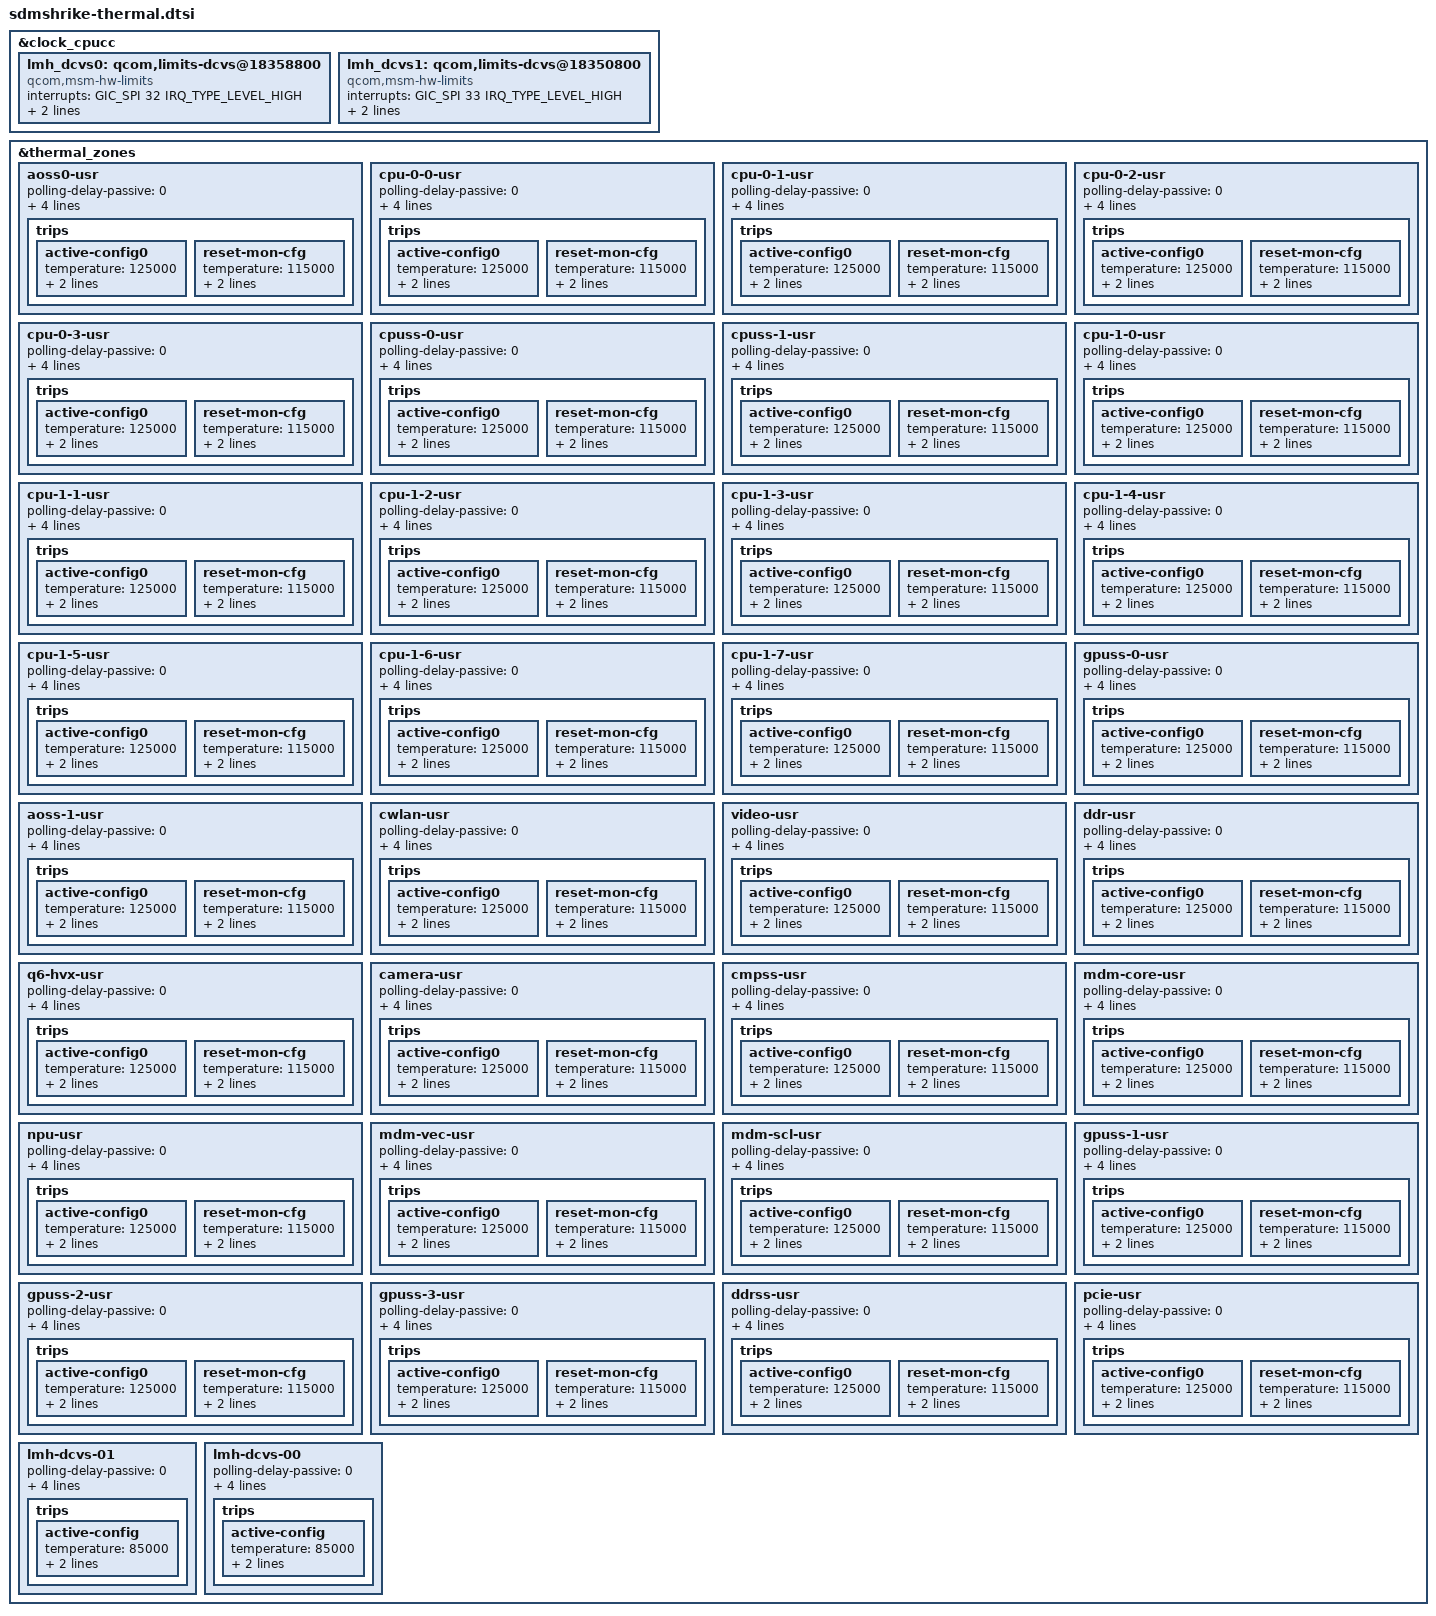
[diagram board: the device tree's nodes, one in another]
/* Copyright (c) 2019, The Linux Foundation. All rights reserved.
 *
 * This program is free software; you can redistribute it and/or modify
 * it under the terms of the GNU General Public License version 2 and
 * only version 2 as published by the Free Software Foundation.
 *
 * This program is distributed in the hope that it will be useful,
 * but WITHOUT ANY WARRANTY; without even the implied warranty of
 * MERCHANTABILITY or FITNESS FOR A PARTICULAR PURPOSE.  See the
 * GNU General Public License for more details.
 */

#include <dt-bindings/thermal/thermal.h>

&clock_cpucc {
	#address-cells = <1>;
	#size-cells = <1>;
	lmh_dcvs0: qcom,limits-dcvs@18358800 {
		compatible = "qcom,msm-hw-limits";
		interrupts = <GIC_SPI 32 IRQ_TYPE_LEVEL_HIGH>;
		qcom,affinity = <0>;
		reg = <0x18358800 0x1000>,
			<0x18323000 0x1000>;
		#thermal-sensor-cells = <0>;
	};

	lmh_dcvs1: qcom,limits-dcvs@18350800 {
		compatible = "qcom,msm-hw-limits";
		interrupts = <GIC_SPI 33 IRQ_TYPE_LEVEL_HIGH>;
		qcom,affinity = <1>;
		reg = <0x18350800 0x1000>,
			<0x18325800 0x1000>;
		#thermal-sensor-cells = <0>;
	};
};

&thermal_zones {
	aoss0-usr {
		polling-delay-passive = <0>;
		polling-delay = <0>;
		thermal-governor = "user_space";
		thermal-sensors = <&tsens0 0>;
		wake-capable-sensor;
		trips {
			active-config0 {
				temperature = <125000>;
				hysteresis = <1000>;
				type = "passive";
			};
			reset-mon-cfg {
				temperature = <115000>;
				hysteresis = <5000>;
				type = "passive";
			};
		};
	};

	cpu-0-0-usr {
		polling-delay-passive = <0>;
		polling-delay = <0>;
		thermal-governor = "user_space";
		thermal-sensors = <&tsens0 1>;
		wake-capable-sensor;
		trips {
			active-config0 {
				temperature = <125000>;
				hysteresis = <1000>;
				type = "passive";
			};
			reset-mon-cfg {
				temperature = <115000>;
				hysteresis = <5000>;
				type = "passive";
			};
		};
	};

	cpu-0-1-usr {
		polling-delay-passive = <0>;
		polling-delay = <0>;
		thermal-governor = "user_space";
		thermal-sensors = <&tsens0 2>;
		wake-capable-sensor;
		trips {
			active-config0 {
				temperature = <125000>;
				hysteresis = <1000>;
				type = "passive";
			};
			reset-mon-cfg {
				temperature = <115000>;
				hysteresis = <5000>;
				type = "passive";
			};
		};
	};

	cpu-0-2-usr {
		polling-delay-passive = <0>;
		polling-delay = <0>;
		thermal-governor = "user_space";
		thermal-sensors = <&tsens0 3>;
		wake-capable-sensor;
		trips {
			active-config0 {
				temperature = <125000>;
				hysteresis = <1000>;
				type = "passive";
			};
			reset-mon-cfg {
				temperature = <115000>;
				hysteresis = <5000>;
				type = "passive";
			};
		};
	};

	cpu-0-3-usr {
		polling-delay-passive = <0>;
		polling-delay = <0>;
		thermal-sensors = <&tsens0 4>;
		thermal-governor = "user_space";
		wake-capable-sensor;
		trips {
			active-config0 {
				temperature = <125000>;
				hysteresis = <1000>;
				type = "passive";
			};
			reset-mon-cfg {
				temperature = <115000>;
				hysteresis = <5000>;
				type = "passive";
			};
		};
	};

	cpuss-0-usr {
		polling-delay-passive = <0>;
		polling-delay = <0>;
		thermal-sensors = <&tsens0 5>;
		thermal-governor = "user_space";
		wake-capable-sensor;
		trips {
			active-config0 {
				temperature = <125000>;
				hysteresis = <1000>;
				type = "passive";
			};
			reset-mon-cfg {
				temperature = <115000>;
				hysteresis = <5000>;
				type = "passive";
			};
		};
	};

	cpuss-1-usr {
		polling-delay-passive = <0>;
		polling-delay = <0>;
		thermal-sensors = <&tsens0 6>;
		thermal-governor = "user_space";
		wake-capable-sensor;
		trips {
			active-config0 {
				temperature = <125000>;
				hysteresis = <1000>;
				type = "passive";
			};
			reset-mon-cfg {
				temperature = <115000>;
				hysteresis = <5000>;
				type = "passive";
			};
		};
	};

	cpu-1-0-usr {
		polling-delay-passive = <0>;
		polling-delay = <0>;
		thermal-sensors = <&tsens0 7>;
		thermal-governor = "user_space";
		wake-capable-sensor;
		trips {
			active-config0 {
				temperature = <125000>;
				hysteresis = <1000>;
				type = "passive";
			};
			reset-mon-cfg {
				temperature = <115000>;
				hysteresis = <5000>;
				type = "passive";
			};
		};
	};

	cpu-1-1-usr {
		polling-delay-passive = <0>;
		polling-delay = <0>;
		thermal-sensors = <&tsens0 8>;
		thermal-governor = "user_space";
		wake-capable-sensor;
		trips {
			active-config0 {
				temperature = <125000>;
				hysteresis = <1000>;
				type = "passive";
			};
			reset-mon-cfg {
				temperature = <115000>;
				hysteresis = <5000>;
				type = "passive";
			};
		};
	};

	cpu-1-2-usr {
		polling-delay-passive = <0>;
		polling-delay = <0>;
		thermal-sensors = <&tsens0 9>;
		thermal-governor = "user_space";
		wake-capable-sensor;
		trips {
			active-config0 {
				temperature = <125000>;
				hysteresis = <1000>;
				type = "passive";
			};
			reset-mon-cfg {
				temperature = <115000>;
				hysteresis = <5000>;
				type = "passive";
			};
		};
	};

	cpu-1-3-usr {
		polling-delay-passive = <0>;
		polling-delay = <0>;
		thermal-sensors = <&tsens0 10>;
		thermal-governor = "user_space";
		wake-capable-sensor;
		trips {
			active-config0 {
				temperature = <125000>;
				hysteresis = <1000>;
				type = "passive";
			};
			reset-mon-cfg {
				temperature = <115000>;
				hysteresis = <5000>;
				type = "passive";
			};
		};
	};

	cpu-1-4-usr {
		polling-delay-passive = <0>;
		polling-delay = <0>;
		thermal-sensors = <&tsens0 11>;
		thermal-governor = "user_space";
		wake-capable-sensor;
		trips {
			active-config0 {
				temperature = <125000>;
				hysteresis = <1000>;
				type = "passive";
			};
			reset-mon-cfg {
				temperature = <115000>;
				hysteresis = <5000>;
				type = "passive";
			};
		};
	};

	cpu-1-5-usr {
		polling-delay-passive = <0>;
		polling-delay = <0>;
		thermal-sensors = <&tsens0 12>;
		thermal-governor = "user_space";
		wake-capable-sensor;
		trips {
			active-config0 {
				temperature = <125000>;
				hysteresis = <1000>;
				type = "passive";
			};
			reset-mon-cfg {
				temperature = <115000>;
				hysteresis = <5000>;
				type = "passive";
			};
		};
	};

	cpu-1-6-usr {
		polling-delay-passive = <0>;
		polling-delay = <0>;
		thermal-sensors = <&tsens0 13>;
		thermal-governor = "user_space";
		wake-capable-sensor;
		trips {
			active-config0 {
				temperature = <125000>;
				hysteresis = <1000>;
				type = "passive";
			};
			reset-mon-cfg {
				temperature = <115000>;
				hysteresis = <5000>;
				type = "passive";
			};
		};
	};

	cpu-1-7-usr {
		polling-delay-passive = <0>;
		polling-delay = <0>;
		thermal-sensors = <&tsens0 14>;
		thermal-governor = "user_space";
		wake-capable-sensor;
		trips {
			active-config0 {
				temperature = <125000>;
				hysteresis = <1000>;
				type = "passive";
			};
			reset-mon-cfg {
				temperature = <115000>;
				hysteresis = <5000>;
				type = "passive";
			};
		};
	};

	gpuss-0-usr {
		polling-delay-passive = <0>;
		polling-delay = <0>;
		thermal-sensors = <&tsens0 15>;
		thermal-governor = "user_space";
		wake-capable-sensor;
		trips {
			active-config0 {
				temperature = <125000>;
				hysteresis = <1000>;
				type = "passive";
			};
			reset-mon-cfg {
				temperature = <115000>;
				hysteresis = <5000>;
				type = "passive";
			};
		};
	};

	aoss-1-usr {
		polling-delay-passive = <0>;
		polling-delay = <0>;
		thermal-sensors = <&tsens1 0>;
		thermal-governor = "user_space";
		wake-capable-sensor;
		trips {
			active-config0 {
				temperature = <125000>;
				hysteresis = <1000>;
				type = "passive";
			};
			reset-mon-cfg {
				temperature = <115000>;
				hysteresis = <5000>;
				type = "passive";
			};
		};
	};

	cwlan-usr {
		polling-delay-passive = <0>;
		polling-delay = <0>;
		thermal-sensors = <&tsens1 1>;
		thermal-governor = "user_space";
		wake-capable-sensor;
		trips {
			active-config0 {
				temperature = <125000>;
				hysteresis = <1000>;
				type = "passive";
			};
			reset-mon-cfg {
				temperature = <115000>;
				hysteresis = <5000>;
				type = "passive";
			};
		};
	};

	video-usr {
		polling-delay-passive = <0>;
		polling-delay = <0>;
		thermal-sensors = <&tsens1 2>;
		thermal-governor = "user_space";
		wake-capable-sensor;
		trips {
			active-config0 {
				temperature = <125000>;
				hysteresis = <1000>;
				type = "passive";
			};
			reset-mon-cfg {
				temperature = <115000>;
				hysteresis = <5000>;
				type = "passive";
			};
		};
	};

	ddr-usr {
		polling-delay-passive = <0>;
		polling-delay = <0>;
		thermal-sensors = <&tsens1 3>;
		thermal-governor = "user_space";
		wake-capable-sensor;
		trips {
			active-config0 {
				temperature = <125000>;
				hysteresis = <1000>;
				type = "passive";
			};
			reset-mon-cfg {
				temperature = <115000>;
				hysteresis = <5000>;
				type = "passive";
			};
		};
	};

	q6-hvx-usr {
		polling-delay-passive = <0>;
		polling-delay = <0>;
		thermal-sensors = <&tsens1 4>;
		thermal-governor = "user_space";
		wake-capable-sensor;
		trips {
			active-config0 {
				temperature = <125000>;
				hysteresis = <1000>;
				type = "passive";
			};
			reset-mon-cfg {
				temperature = <115000>;
				hysteresis = <5000>;
				type = "passive";
			};
		};
	};

	camera-usr {
		polling-delay-passive = <0>;
		polling-delay = <0>;
		thermal-sensors = <&tsens1 5>;
		thermal-governor = "user_space";
		wake-capable-sensor;
		trips {
			active-config0 {
				temperature = <125000>;
				hysteresis = <1000>;
				type = "passive";
			};
			reset-mon-cfg {
				temperature = <115000>;
				hysteresis = <5000>;
				type = "passive";
			};
		};
	};

	cmpss-usr {
		polling-delay-passive = <0>;
		polling-delay = <0>;
		thermal-sensors = <&tsens1 6>;
		thermal-governor = "user_space";
		wake-capable-sensor;
		trips {
			active-config0 {
				temperature = <125000>;
				hysteresis = <1000>;
				type = "passive";
			};
			reset-mon-cfg {
				temperature = <115000>;
				hysteresis = <5000>;
				type = "passive";
			};
		};
	};

	mdm-core-usr {
		polling-delay-passive = <0>;
		polling-delay = <0>;
		thermal-sensors = <&tsens1 7>;
		thermal-governor = "user_space";
		wake-capable-sensor;
		trips {
			active-config0 {
				temperature = <125000>;
				hysteresis = <1000>;
				type = "passive";
			};
			reset-mon-cfg {
				temperature = <115000>;
				hysteresis = <5000>;
				type = "passive";
			};
		};
	};

	npu-usr {
		polling-delay-passive = <0>;
		polling-delay = <0>;
		thermal-sensors = <&tsens1 8>;
		thermal-governor = "user_space";
		wake-capable-sensor;
		trips {
			active-config0 {
				temperature = <125000>;
				hysteresis = <1000>;
				type = "passive";
			};
			reset-mon-cfg {
				temperature = <115000>;
				hysteresis = <5000>;
				type = "passive";
			};
		};
	};

	mdm-vec-usr {
		polling-delay-passive = <0>;
		polling-delay = <0>;
		thermal-sensors = <&tsens1 9>;
		thermal-governor = "user_space";
		wake-capable-sensor;
		trips {
			active-config0 {
				temperature = <125000>;
				hysteresis = <1000>;
				type = "passive";
			};
			reset-mon-cfg {
				temperature = <115000>;
				hysteresis = <5000>;
				type = "passive";
			};
		};
	};

	mdm-scl-usr {
		polling-delay-passive = <0>;
		polling-delay = <0>;
		thermal-sensors = <&tsens1 10>;
		thermal-governor = "user_space";
		wake-capable-sensor;
		trips {
			active-config0 {
				temperature = <125000>;
				hysteresis = <1000>;
				type = "passive";
			};
			reset-mon-cfg {
				temperature = <115000>;
				hysteresis = <5000>;
				type = "passive";
			};
		};
	};

	gpuss-1-usr {
		polling-delay-passive = <0>;
		polling-delay = <0>;
		thermal-governor = "user_space";
		thermal-sensors = <&tsens1 11>;
		wake-capable-sensor;
		trips {
			active-config0 {
				temperature = <125000>;
				hysteresis = <1000>;
				type = "passive";
			};
			reset-mon-cfg {
				temperature = <115000>;
				hysteresis = <5000>;
				type = "passive";
			};
		};
	};

	gpuss-2-usr {
		polling-delay-passive = <0>;
		polling-delay = <0>;
		thermal-governor = "user_space";
		thermal-sensors = <&tsens1 12>;
		wake-capable-sensor;
		trips {
			active-config0 {
				temperature = <125000>;
				hysteresis = <1000>;
				type = "passive";
			};
			reset-mon-cfg {
				temperature = <115000>;
				hysteresis = <5000>;
				type = "passive";
			};
		};
	};

	gpuss-3-usr {
		polling-delay-passive = <0>;
		polling-delay = <0>;
		thermal-governor = "user_space";
		thermal-sensors = <&tsens1 13>;
		wake-capable-sensor;
		trips {
			active-config0 {
				temperature = <125000>;
				hysteresis = <1000>;
				type = "passive";
			};
			reset-mon-cfg {
				temperature = <115000>;
				hysteresis = <5000>;
				type = "passive";
			};
		};
	};

	ddrss-usr {
		polling-delay-passive = <0>;
		polling-delay = <0>;
		thermal-governor = "user_space";
		thermal-sensors = <&tsens1 14>;
		wake-capable-sensor;
		trips {
			active-config0 {
				temperature = <125000>;
				hysteresis = <1000>;
				type = "passive";
			};
			reset-mon-cfg {
				temperature = <115000>;
				hysteresis = <5000>;
				type = "passive";
			};
		};
	};

	pcie-usr {
		polling-delay-passive = <0>;
		polling-delay = <0>;
		thermal-governor = "user_space";
		thermal-sensors = <&tsens1 15>;
		wake-capable-sensor;
		trips {
			active-config0 {
				temperature = <125000>;
				hysteresis = <1000>;
				type = "passive";
			};
			reset-mon-cfg {
				temperature = <115000>;
				hysteresis = <5000>;
				type = "passive";
			};
		};
	};

	lmh-dcvs-01 {
		polling-delay-passive = <0>;
		polling-delay = <0>;
		thermal-governor = "user_space";
		thermal-sensors = <&lmh_dcvs1>;
		wake-capable-sensor;

		trips {
			active-config {
				temperature = <85000>;
				hysteresis = <25000>;
				type = "passive";
			};
		};
	};

	lmh-dcvs-00 {
		polling-delay-passive = <0>;
		polling-delay = <0>;
		thermal-governor = "user_space";
		thermal-sensors = <&lmh_dcvs0>;
		wake-capable-sensor;

		trips {
			active-config {
				temperature = <85000>;
				hysteresis = <25000>;
				type = "passive";
			};
		};
	};
};
